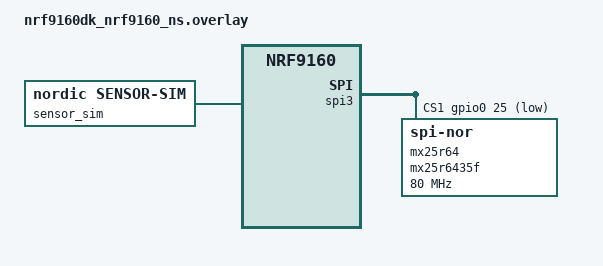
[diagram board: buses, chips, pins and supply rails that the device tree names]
/*
 * Copyright (c) 2021 Nordic Semiconductor ASA
 *
 * SPDX-License-Identifier: LicenseRef-Nordic-5-Clause
 */

#include <samples/cellular/nrf91_bootloader_partitions.dtsi>

#include <samples/cellular/nrf91_sram_partitions.dtsi>

/ {
	sensor_sim: sensor-sim {
		compatible = "nordic,sensor-sim";
		acc-signal = "wave";
	};
};

&spi3 {
	cs-gpios = <&arduino_header 16 GPIO_ACTIVE_LOW>, /* D10 */
		   <&gpio0 25 GPIO_ACTIVE_LOW>;

	mx25r64: mx25r6435f@1 {
		compatible = "jedec,spi-nor";
		reg = <1>;
		status = "okay";
		spi-max-frequency = <80000000>;
		jedec-id = [c2 28 17];
		size = <67108864>;
	};
};
